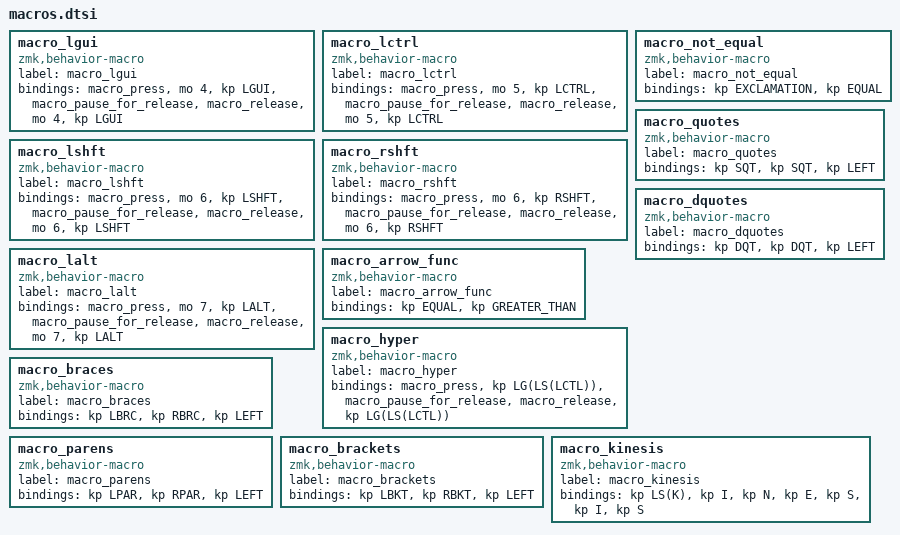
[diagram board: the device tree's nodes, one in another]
macro_lgui: macro_lgui{
compatible = "zmk,behavior-macro";
label = "macro_lgui";
#binding-cells = <0>;
bindings
    = <&macro_press &mo 4 &kp LGUI>
    , <&macro_pause_for_release>
    , <&macro_release &mo 4 &kp LGUI>;
};
macro_lctrl: macro_lctrl{
compatible = "zmk,behavior-macro";
label = "macro_lctrl";
#binding-cells = <0>;
bindings
    = <&macro_press &mo 5 &kp LCTRL>
    , <&macro_pause_for_release>
    , <&macro_release &mo 5 &kp LCTRL>;
};
macro_lshft: macro_lshft{
compatible = "zmk,behavior-macro";
label = "macro_lshft";
#binding-cells = <0>;
bindings
    = <&macro_press &mo 6 &kp LSHFT>
    , <&macro_pause_for_release>
    , <&macro_release &mo 6 &kp LSHFT>;
};
macro_rshft: macro_rshft{
compatible = "zmk,behavior-macro";
label = "macro_rshft";
#binding-cells = <0>;
bindings
    = <&macro_press &mo 6 &kp RSHFT>
    , <&macro_pause_for_release>
    , <&macro_release &mo 6 &kp RSHFT>;
};
macro_lalt: macro_lalt{
compatible = "zmk,behavior-macro";
label = "macro_lalt";
#binding-cells = <0>;
bindings
    = <&macro_press &mo 7 &kp LALT>
    , <&macro_pause_for_release>
    , <&macro_release &mo 7 &kp LALT>;
};
macro_not_equal: macro_not_equal{
compatible = "zmk,behavior-macro";
label = "macro_not_equal";
#binding-cells = <0>;
bindings = <&kp EXCLAMATION>, <&kp EQUAL>;
};
macro_arrow_func: macro_arrow_func{
compatible = "zmk,behavior-macro";
label = "macro_arrow_func";
#binding-cells = <0>;
bindings = <&kp EQUAL>, <&kp GREATER_THAN>;
};
macro_hyper: macro_hyper{
compatible = "zmk,behavior-macro";
label = "macro_hyper";
#binding-cells = <0>;
bindings
    = <&macro_press &kp LG(LS(LCTL))>
    , <&macro_pause_for_release>
    , <&macro_release &kp LG(LS(LCTL))>;
};
macro_quotes: macro_quotes{
compatible = "zmk,behavior-macro";
label = "macro_quotes";
#binding-cells = <0>;
bindings = <&kp SQT>, <&kp SQT>, <&kp LEFT>;
};
macro_dquotes: macro_dquotes{
compatible = "zmk,behavior-macro";
label = "macro_dquotes";
#binding-cells = <0>;
bindings = <&kp DQT>, <&kp DQT>, <&kp LEFT>;
};
macro_braces: macro_braces{
compatible = "zmk,behavior-macro";
label = "macro_braces";
#binding-cells = <0>;
bindings = <&kp LBRC>, <&kp RBRC>, <&kp LEFT>;
};
macro_parens: macro_parens{
compatible = "zmk,behavior-macro";
label = "macro_parens";
#binding-cells = <0>;
bindings = <&kp LPAR>, <&kp RPAR>, <&kp LEFT>;
};
macro_brackets: macro_brackets{
compatible = "zmk,behavior-macro";
label = "macro_brackets";
#binding-cells = <0>;
bindings = <&kp LBKT>, <&kp RBKT>, <&kp LEFT>;
};
macro_kinesis: macro_kinesis{
compatible = "zmk,behavior-macro";
label = "macro_kinesis";
#binding-cells = <0>;
bindings = <&kp LS(K)>, <&kp I>, <&kp N>, <&kp E>, <&kp S>, <&kp I>, <&kp S>;
};
